# ATtiny841 register map
Vendor: Atmel; File version: 1.0
CPU: other r0p0, little endian, no MPU, no FPU, 4 interrupt priority bits
Registers are 8-bit, read-write, reset 0x0 unless marked. A register's access mark holds for its fields unless they carry their own. Offsets are from the block's base; [hi:lo] are bit positions; {n}, {i} and the like mark numbered series.

## LOCKBIT — Lockbits
Base 0x00800000
0x00 LOCKBIT
  [1:0] LB — Memory Lock
    0=PROG_VER_DISABLED (Further programming and verification disabled); 2=PROG_DISABLED (Further programming disabled); 3=NO_LOCK (No memory lock features enabled)

## PORTA — I/O Port
Base 0x00800039
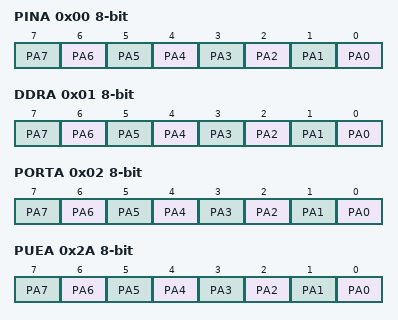
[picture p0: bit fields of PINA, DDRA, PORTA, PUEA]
0x00 PINA — Port A Input Pins
  [n] PA{n} (n=0..7) — Pin A{n}
0x01 DDRA — Data Direction Register, Port A
  [n] PA{n} (n=0..7) — Pin A{n}
0x02 PORTA — Port A Data Register
  [n] PA{n} (n=0..7) — Pin A{n}
0x2A PUEA — Pull-up Enable Control Register
  [n] PA{n} (n=0..7) — Pin A{n}
0x2B PORTCR — Port Control Register
  [0] BBMA — Break-Before-Make Mode Enable
0x31 PHDE — Port High Drive Enable Register
  [1:0] PHDEA — PortA High Drive Enable

## PORTB — I/O Port
Base 0x00800036
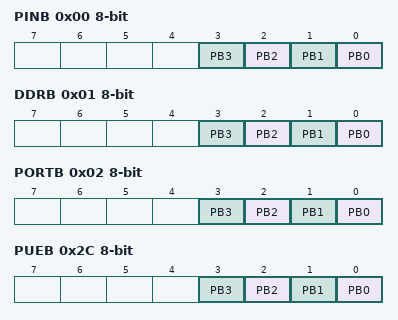
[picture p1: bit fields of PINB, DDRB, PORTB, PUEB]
0x00 PINB — Port B Data register
  [n] PB{n} (n=0..3) — Pin B{n}
0x01 DDRB — Data Direction Register, Port B
  [n] PB{n} (n=0..3) — Pin B{n}
0x02 PORTB — Input Pins, Port B
  [n] PB{n} (n=0..3) — Pin B{n}
0x2C PUEB — Pull-up Enable Control Register
  [n] PB{n} (n=0..3) — Pin B{n}
0x2E PORTCR — Port Control Register
  [1] BBMB — Break-Before-Make Mode Enable

## SPI — Serial Peripheral Interface
Base 0x00800065
0x00 REMAP — Remap Port Pins
  [1] SPIMAP — SPI Pin Mapping
0x4B SPDR — SPI Data Register (write-only for debugger)
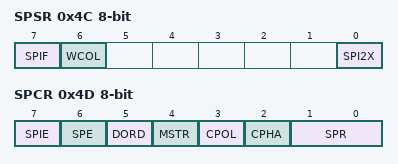
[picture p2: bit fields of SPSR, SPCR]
0x4C SPSR — SPI Status Register
  [7] SPIF — SPI Interrupt Flag
  [6] WCOL — Write Collision Flag
  [0] SPI2X — Double SPI Speed Bit
0x4D SPCR — SPI Control Register
  [7] SPIE — SPI Interrupt Enable
  [6] SPE — SPI Enable
  [5] DORD — Data Order
  [4] MSTR — Master/Slave Select
  [3] CPOL — Clock polarity
  [2] CPHA — Clock Phase
  [1:0] SPR — SPI Clock Rate Selects
    0=FCL_4; 1=FCL_16; 2=FCL_64; 3=FCL_128

## TC0 — Timer/Counter, 8-bit
Base 0x00800043
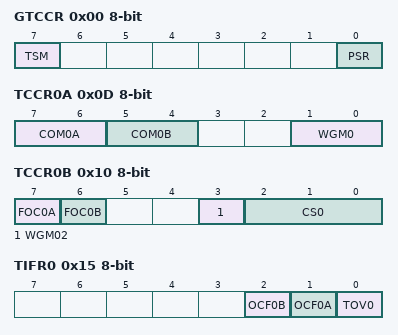
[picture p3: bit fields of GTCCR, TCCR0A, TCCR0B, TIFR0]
0x00 GTCCR — General Timer/Counter Control Register
  [7] TSM — Timer/Counter Synchronization Mode
  [0] PSR — Prescaler Reset Timer/CounterN
0x0D TCCR0A — Timer/Counter Control Register A
  [7:6] COM0A — Compare Match Output A Mode bits
  [5:4] COM0B — Compare Match Output B Mode bits
  [1:0] WGM0 — Waveform Generation Mode bits
0x0F TCNT0 — Timer/Counter0
0x10 TCCR0B — Timer/Counter Control Register B
  [7] FOC0A — Force Output Compare A
  [6] FOC0B — Force Output Compare B
  [3] WGM02 — Waveform Generation Mode bit 2
  [2:0] CS0 — Clock Select bits
    0=NO_CLOCK_SOURCE_STOPPED; 1=RUNNING_NO_PRESCALING; 2=RUNNING_CLK_8; 3=RUNNING_CLK_64; 4=RUNNING_CLK_256; 5=RUNNING_CLK_1024; 6=RUNNING_EXTCLK_TN_FALLING_EDGE; 7=RUNNING_EXTCLK_TN_RISING_EDGE
0x13 OCR0A — Timer/Counter0 Output Compare Register A
0x15 TIFR0 — Timer/Counter0 Interrupt Flag Register (read-only for debugger)
  [2] OCF0B — Timer/Counter0 Output Compare Flag B
  [1] OCF0A — Timer/Counter0 Output Compare Flag A
  [0] TOV0 — Timer/Counter0 Overflow Flag
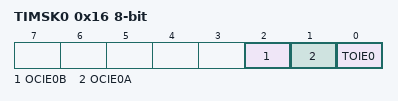
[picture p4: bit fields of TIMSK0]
0x16 TIMSK0 — Timer/Counter Interrupt Mask Register
  [2] OCIE0B — Timer/Counter0 Output Compare Match B Interrupt Enable
  [1] OCIE0A — Timer/Counter0 Output Compare Match A Interrupt Enable
  [0] TOIE0 — Timer/Counter0 Overflow Interrupt Enable
0x19 OCR0B — Timer/Counter0 Output Compare Register B

## TC1 — Timer/Counter, 16-bit
Base 0x0080002E
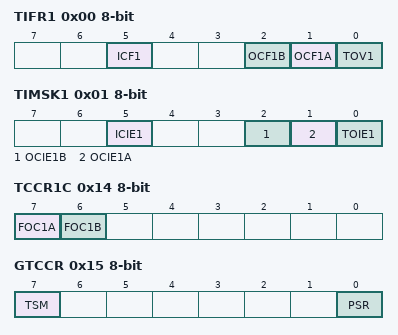
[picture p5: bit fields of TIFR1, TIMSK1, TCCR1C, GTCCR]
0x00 TIFR1 — Timer/Counter Interrupt Flag register (read-only for debugger)
  [5] ICF1 — Timer/Counter1 Input Capture Flag
  [2] OCF1B — Timer/Counter1 Output Compare B Match Flag
  [1] OCF1A — Timer/Counter1 Output Compare A Match Flag
  [0] TOV1 — Timer/Counter1 Overflow Flag
0x01 TIMSK1 — Timer/Counter1 Interrupt Mask Register
  [5] ICIE1 — Timer/Counter1 Input Capture Interrupt Enable
  [2] OCIE1B — Timer/Counter1 Output Compare B Match Interrupt Enable
  [1] OCIE1A — Timer/Counter1 Output Compare A Match Interrupt Enable
  [0] TOIE1 — Timer/Counter1 Overflow Interrupt Enable
0x14 TCCR1C — Timer/Counter1 Control Register C (write-only for debugger)
  [7] FOC1A — Force Output Compare for Channel A
  [6] FOC1B — Force Output Compare for Channel B
0x15 GTCCR — General Timer/Counter Control Register
  [7] TSM — Timer/Counter Synchronization Mode
  [0] PSR — Prescaler Reset Timer/CounterN
0x16 ICR1 16-bit (reset mask 0xFF) — Timer/Counter1 Input Capture Register Bytes
0x1A OCR1B 16-bit (reset mask 0xFF) — Timer/Counter1 Output Compare Register B Bytes
0x1C OCR1A 16-bit (reset mask 0xFF) — Timer/Counter1 Output Compare Register A Bytes
0x1E TCNT1 16-bit (reset mask 0xFF) — Timer/Counter1 Bytes
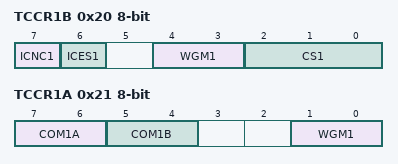
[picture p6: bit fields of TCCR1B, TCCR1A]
0x20 TCCR1B — Timer/Counter1 Control Register B
  [7] ICNC1 — Input Capture 1 Noise Canceler
  [6] ICES1 — Input Capture 1 Edge Select
  [4:3] WGM1 — Waveform Generation Mode Bits
  [2:0] CS1 — Clock Select bits
    0=NO_CLOCK_SOURCE_STOPPED; 1=RUNNING_NO_PRESCALING; 2=RUNNING_CLK_8; 3=RUNNING_CLK_64; 4=RUNNING_CLK_256; 5=RUNNING_CLK_1024; 6=RUNNING_EXTCLK_TN_FALLING_EDGE; 7=RUNNING_EXTCLK_TN_RISING_EDGE
0x21 TCCR1A — Timer/Counter1 Control Register A
  [7:6] COM1A — Compare Output Mode 1A, bits
  [5:4] COM1B — Compare Output Mode 1B, bits
  [1:0] WGM1 — Pulse Width Modulator Select Bits
